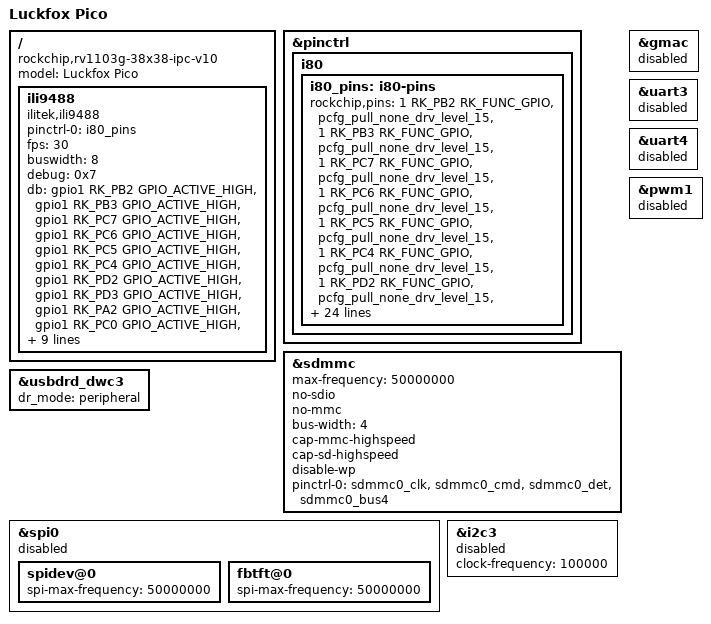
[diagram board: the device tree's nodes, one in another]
// SPDX-License-Identifier: (GPL-2.0+ OR MIT)
/*
 * Copyright (c) 2022 Rockchip Electronics Co., Ltd.
 */

/dts-v1/;

#include "rv1103.dtsi"
#include "rv1106-evb.dtsi"
#include "rv1103-luckfox-pico-ipc.dtsi"

/ {
	model = "Luckfox Pico";
	compatible = "rockchip,rv1103g-38x38-ipc-v10", "rockchip,rv1103";

	ili9488 {
		status = "okay";
		compatible = "ilitek,ili9488";
		pinctrl-names = "default";
		pinctrl-0 = <&i80_pins>;
		fps = <30>;
		buswidth = <8>;
		debug = <0x7>;
		db =	<&gpio1 RK_PB2 GPIO_ACTIVE_HIGH>,
				<&gpio1 RK_PB3 GPIO_ACTIVE_HIGH>,
				<&gpio1 RK_PC7 GPIO_ACTIVE_HIGH>,
				<&gpio1 RK_PC6 GPIO_ACTIVE_HIGH>,
				<&gpio1 RK_PC5 GPIO_ACTIVE_HIGH>,
				<&gpio1 RK_PC4 GPIO_ACTIVE_HIGH>,
				<&gpio1 RK_PD2 GPIO_ACTIVE_HIGH>,
				<&gpio1 RK_PD3 GPIO_ACTIVE_HIGH>,
				<&gpio1 RK_PA2 GPIO_ACTIVE_HIGH>,
				<&gpio1 RK_PC0 GPIO_ACTIVE_HIGH>,
				<&gpio1 RK_PC1 GPIO_ACTIVE_HIGH>,
				<&gpio1 RK_PC2 GPIO_ACTIVE_HIGH>,
				<&gpio1 RK_PC3 GPIO_ACTIVE_HIGH>,
				<&gpio0 RK_PA4 GPIO_ACTIVE_HIGH>,
				<&gpio1 RK_PD0 GPIO_ACTIVE_HIGH>,
				<&gpio1 RK_PD1 GPIO_ACTIVE_HIGH>;

				dc = <&gpio4 RK_PA3 GPIO_ACTIVE_HIGH>;      //RS
				wr = <&gpio4 RK_PA2 GPIO_ACTIVE_HIGH>;
				reset = <&gpio4 RK_PA6 GPIO_ACTIVE_HIGH>;    //RESET
	};
};

&pinctrl {
	i80 {
		i80_pins: i80-pins {
			rockchip,pins =
				<1 RK_PB2 RK_FUNC_GPIO &pcfg_pull_none_drv_level_15>,
				<1 RK_PB3 RK_FUNC_GPIO &pcfg_pull_none_drv_level_15>,
				<1 RK_PC7 RK_FUNC_GPIO &pcfg_pull_none_drv_level_15>,
				<1 RK_PC6 RK_FUNC_GPIO &pcfg_pull_none_drv_level_15>,
				<1 RK_PC5 RK_FUNC_GPIO &pcfg_pull_none_drv_level_15>,
				<1 RK_PC4 RK_FUNC_GPIO &pcfg_pull_none_drv_level_15>,
				<1 RK_PD2 RK_FUNC_GPIO &pcfg_pull_none_drv_level_15>,
				<1 RK_PD3 RK_FUNC_GPIO &pcfg_pull_none_drv_level_15>,
				<1 RK_PA2 RK_FUNC_GPIO &pcfg_pull_none_drv_level_15>,
				<1 RK_PC0 RK_FUNC_GPIO &pcfg_pull_none_drv_level_15>,
				<1 RK_PC1 RK_FUNC_GPIO &pcfg_pull_none_drv_level_15>,
				<1 RK_PC2 RK_FUNC_GPIO &pcfg_pull_none_drv_level_15>,
				<1 RK_PC3 RK_FUNC_GPIO &pcfg_pull_none_drv_level_15>,
				<0 RK_PA4 RK_FUNC_GPIO &pcfg_pull_none_drv_level_15>,
				<1 RK_PD0 RK_FUNC_GPIO &pcfg_pull_none_drv_level_15>,
				<1 RK_PD1 RK_FUNC_GPIO &pcfg_pull_none_drv_level_15>,
				<4 RK_PA3 RK_FUNC_GPIO &pcfg_pull_none_drv_level_15>,
				<4 RK_PA2 RK_FUNC_GPIO &pcfg_pull_none_drv_level_15>,
				<4 RK_PA6 RK_FUNC_GPIO &pcfg_pull_none_drv_level_15>;
		};
	};
};

/**********SDMMC**********/
&sdmmc {
	max-frequency = <50000000>;
	no-sdio;
	no-mmc;
	bus-width = <4>;
	cap-mmc-highspeed;
	cap-sd-highspeed;
	disable-wp;
	pinctrl-names = "default";
	pinctrl-0 = <&sdmmc0_clk &sdmmc0_cmd &sdmmc0_det &sdmmc0_bus4>;
	status = "okay";
};

/**********ETH**********/
&gmac {
	status = "disabled";
};

/**********USB**********/
&usbdrd_dwc3 {
	status = "okay";
	dr_mode = "peripheral";
};

/**********SPI**********/
/* SPI0_M0 */
&spi0 {
	status = "disabled";
	spidev@0 {
		spi-max-frequency = <50000000>;
	};
  fbtft@0 {
    spi-max-frequency = <50000000>;
  };
};

/**********I2C**********/
/* I2C3_M1 */
&i2c3 {
	status = "disabled";
	clock-frequency = <100000>;
};

/**********UART**********/
/* UART3_M1 */
&uart3 {
	status = "disabled";
};

/* UART4_M1 */
&uart4 {
	status = "disabled";
};

/**********PWM**********/
/* PWM1_M0 */
&pwm1 {
	status = "disabled";
};
